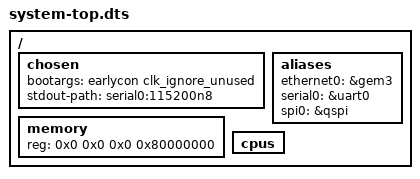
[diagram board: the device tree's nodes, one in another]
/*
 * CAUTION: This file is automatically generated by Xilinx.
 * Version:  
 * Today is: Sat Jan  6 00:05:10 2018
 */


/dts-v1/;
/include/ "zynqmp.dtsi"
/include/ "zynqmp-clk-ccf.dtsi"
/include/ "pl.dtsi"
/include/ "pcw.dtsi"
/ {
	chosen {
		bootargs = "earlycon clk_ignore_unused";
		stdout-path = "serial0:115200n8";
	};
	aliases {
		ethernet0 = &gem3;
		serial0 = &uart0;
		spi0 = &qspi;
	};
	memory {
		device_type = "memory";
		reg = <0x0 0x0 0x0 0x80000000>;
	};
	cpus {
		/delete-node/ cpu@2 ;
		/delete-node/ cpu@3 ;
	};
};
#include "system-user.dtsi"
